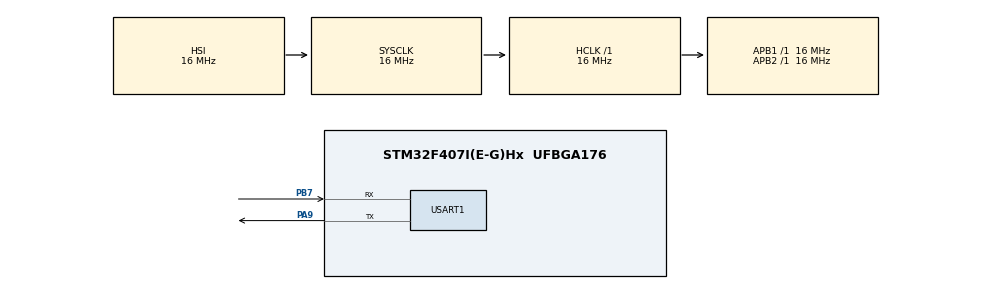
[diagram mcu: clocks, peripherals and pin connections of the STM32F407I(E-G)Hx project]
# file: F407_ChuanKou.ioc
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Dma.Request0=USART1_TX
Dma.USART1_TX.0.Direction=DMA_MEMORY_TO_PERIPH
Dma.USART1_TX.0.FIFOMode=DMA_FIFOMODE_DISABLE
Dma.USART1_TX.0.Instance=DMA2_Stream7
Dma.USART1_TX.0.MemDataAlignment=DMA_MDATAALIGN_BYTE
Dma.USART1_TX.0.MemInc=DMA_MINC_ENABLE
Dma.USART1_TX.0.Mode=DMA_NORMAL
Dma.USART1_TX.0.PeriphDataAlignment=DMA_PDATAALIGN_BYTE
Dma.USART1_TX.0.PeriphInc=DMA_PINC_DISABLE
Dma.USART1_TX.0.Priority=DMA_PRIORITY_VERY_HIGH
Mcu.Family=STM32F4
Mcu.Name=STM32F407I(E-G)Hx
Mcu.Package=UFBGA176
NVIC.DMA2_Stream7_IRQn=true\:0\:0\:false\:false\:true\:false\:true\:true
NVIC.PriorityGroup=NVIC_PRIORITYGROUP_4
NVIC.USART1_IRQn=true\:0\:0\:false\:false\:true\:true\:true\:true
PA13.Mode=Serial_Wire
PA13.Signal=SYS_JTMS-SWDIO
PA14.Mode=Serial_Wire
PA14.Signal=SYS_JTCK-SWCLK
PA9.Mode=Asynchronous
PA9.Signal=USART1_TX
PB7.Mode=Asynchronous
PB7.Signal=USART1_RX
PH0-OSC_IN.Mode=HSE-External-Oscillator
PH0-OSC_IN.Signal=RCC_OSC_IN
PH1-OSC_OUT.Mode=HSE-External-Oscillator
PH1-OSC_OUT.Signal=RCC_OSC_OUT
ProjectManager.HeapSize=0x200
ProjectManager.StackSize=0x400
ProjectManager.TargetToolchain=MDK-ARM V5.32
RCC.AHBFreq_Value=16000000
RCC.APB1Freq_Value=16000000
RCC.APB2Freq_Value=16000000
RCC.CortexFreq_Value=16000000
RCC.HSE_VALUE=25000000
RCC.HSI_VALUE=16000000
RCC.LSE_VALUE=32768
RCC.SYSCLKFreq_VALUE=16000000
RCC.VCOOutputFreq_Value=192000000
USART1.VirtualMode=VM_ASYNC
board=custom

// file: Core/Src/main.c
/* USER CODE BEGIN Header */
/**
  ******************************************************************************
  * @file           : main.c
  * @brief          : Main program body
  ******************************************************************************
  * @attention
  *
  * Copyright (c) 2025 STMicroelectronics.
  * All rights reserved.
  *
  * This software is licensed under terms that can be found in the LICENSE file
  * in the root directory of this software component.
  * If no LICENSE file comes with this software, it is provided AS-IS.
  *
  ******************************************************************************
  */
/* USER CODE END Header */
#include "main.h"
#include "dma.h"
#include "usart.h"
#include "gpio.h"

/* USER CODE BEGIN Includes */
uint8_t UARTBUF[100];
uint8_t len=0;
/* USER CODE END Includes */

void SystemClock_Config(void);

int main(void)
{

  /* MCU Configuration--------------------------------------------------------*/

  /* Reset of all peripherals, Initializes the Flash interface and the Systick. */
  HAL_Init();

  /* Configure the system clock */
  SystemClock_Config();

  /* Initialize all configured peripherals */
  MX_GPIO_Init();
  MX_DMA_Init();
  MX_USART1_UART_Init();
  /* USER CODE BEGIN 2 */
    __HAL_UART_ENABLE_IT(&huart1, UART_IT_RXNE);
    __HAL_UART_ENABLE_IT(&huart1, UART_IT_IDLE);
  /* USER CODE END 2 */

  /* Infinite loop */
  while (1)
  {

    /* USER CODE BEGIN 3 */
    HAL_UART_Transmit(&huart1,(uint8_t*)"ABCDEF\r\n",8,100);
		HAL_Delay (200);
	}
  /* USER CODE END 3 */
}

void SystemClock_Config(void)
{
  RCC_OscInitTypeDef RCC_OscInitStruct = {0};
  RCC_ClkInitTypeDef RCC_ClkInitStruct = {0};

  /** Configure the main internal regulator output voltage
  */
  __HAL_RCC_PWR_CLK_ENABLE();
  __HAL_PWR_VOLTAGESCALING_CONFIG(PWR_REGULATOR_VOLTAGE_SCALE1);

  /** Initializes the RCC Oscillators according to the specified parameters
  * in the RCC_OscInitTypeDef structure.
  */
  RCC_OscInitStruct.OscillatorType = RCC_OSCILLATORTYPE_HSI;
  RCC_OscInitStruct.HSIState = RCC_HSI_ON;
  RCC_OscInitStruct.HSICalibrationValue = RCC_HSICALIBRATION_DEFAULT;
  RCC_OscInitStruct.PLL.PLLState = RCC_PLL_NONE;
  if (HAL_RCC_OscConfig(&RCC_OscInitStruct) != HAL_OK)
  {
    Error_Handler();
  }

  /** Initializes the CPU, AHB and APB buses clocks
  */
  RCC_ClkInitStruct.ClockType = RCC_CLOCKTYPE_HCLK|RCC_CLOCKTYPE_SYSCLK
                              |RCC_CLOCKTYPE_PCLK1|RCC_CLOCKTYPE_PCLK2;
  RCC_ClkInitStruct.SYSCLKSource = RCC_SYSCLKSOURCE_HSI;
  RCC_ClkInitStruct.AHBCLKDivider = RCC_SYSCLK_DIV1;
  RCC_ClkInitStruct.APB1CLKDivider = RCC_HCLK_DIV1;
  RCC_ClkInitStruct.APB2CLKDivider = RCC_HCLK_DIV1;

  if (HAL_RCC_ClockConfig(&RCC_ClkInitStruct, FLASH_LATENCY_0) != HAL_OK)
  {
    Error_Handler();
  }
}

void Error_Handler(void)
{
  __disable_irq();
  while (1)
  {
  }
}
